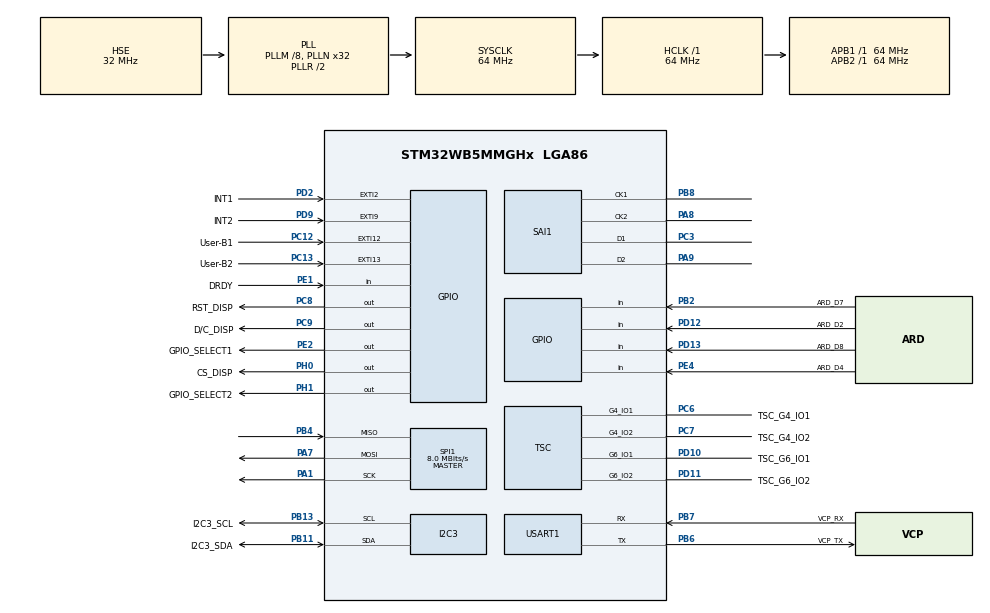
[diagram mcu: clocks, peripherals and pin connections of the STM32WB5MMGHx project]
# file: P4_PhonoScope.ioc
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Dma.Request0=SAI1_A
Dma.SAI1_A.0.Direction=DMA_PERIPH_TO_MEMORY
Dma.SAI1_A.0.EventEnable=DISABLE
Dma.SAI1_A.0.Instance=DMA1_Channel1
Dma.SAI1_A.0.MemDataAlignment=DMA_MDATAALIGN_WORD
Dma.SAI1_A.0.MemInc=DMA_MINC_ENABLE
Dma.SAI1_A.0.Mode=DMA_CIRCULAR
Dma.SAI1_A.0.PeriphDataAlignment=DMA_PDATAALIGN_WORD
Dma.SAI1_A.0.PeriphInc=DMA_PINC_DISABLE
Dma.SAI1_A.0.Polarity=HAL_DMAMUX_REQ_GEN_RISING
Dma.SAI1_A.0.Priority=DMA_PRIORITY_LOW
Dma.SAI1_A.0.RequestNumber=1
Dma.SAI1_A.0.SignalID=NONE
Dma.SAI1_A.0.SyncEnable=DISABLE
Dma.SAI1_A.0.SyncPolarity=HAL_DMAMUX_SYNC_NO_EVENT
Dma.SAI1_A.0.SyncRequestNumber=1
Dma.SAI1_A.0.SyncSignalID=NONE
FREERTOS.Tasks01=defaultTask,24,128,StartDefaultTask,Default,NULL,Dynamic,NULL,NULL
FREERTOS.configCHECK_FOR_STACK_OVERFLOW=2
FREERTOS.configTOTAL_HEAP_SIZE=16384
FREERTOS.configUSE_IDLE_HOOK=1
I2C3.SMBusAddressingMode=SMBUS_ADDRESSINGMODE_7BIT
I2C3.Timeout=0x0000830D
I2C3.Timing=0x10B17DB5
Mcu.Family=STM32WB
Mcu.Name=STM32WB5MMGHx
Mcu.Package=LGA86
NVIC.DMA1_Channel1_IRQn=true\:5\:0\:false\:false\:true\:true\:false\:true\:true
NVIC.EXTI15_10_IRQn=true\:5\:0\:false\:false\:true\:true\:true\:true\:true
NVIC.EXTI2_IRQn=true\:5\:0\:false\:false\:true\:true\:true\:true\:true
NVIC.EXTI9_5_IRQn=true\:5\:0\:false\:false\:true\:true\:true\:true\:true
NVIC.PriorityGroup=NVIC_PRIORITYGROUP_4
NVIC.SAI1_IRQn=true\:5\:0\:false\:false\:true\:true\:true\:true\:true
NVIC.TIM1_TRG_COM_TIM17_IRQn=true\:15\:0\:false\:false\:true\:false\:false\:true\:true
NVIC.TimeBase=TIM1_TRG_COM_TIM17_IRQn
NVIC.TimeBaseIP=TIM17
PA1.Mode=Full_Duplex_Master
PA1.Signal=SPI1_SCK
PA13.GPIO_Label=T_SWDIO
PA13.Signal=SYS_JTMS-SWDIO
PA14.GPIO_Label=T_SWCLK
PA14.Signal=SYS_JTCK-SWCLK
PA3.Signal=QUADSPI_CLK
PA7.Mode=Full_Duplex_Master
PA7.Signal=SPI1_MOSI
PA8.Mode=CK2
PA8.Signal=SAI1_CK2
PA9.Mode=3_4_MicroPhones
PA9.Signal=SAI1_D2
PB11.GPIO_Label=I2C3_SDA
PB11.GPIO_Pu=GPIO_PULLUP
PB11.Mode=I2C
PB11.Signal=I2C3_SDA
PB13.GPIO_Label=I2C3_SCL
PB13.GPIO_Pu=GPIO_PULLUP
PB13.Mode=I2C
PB13.Signal=I2C3_SCL
PB2.GPIO_Label=ARD_D7
PB2.Signal=GPIO_Input
PB3.GPIO_Label=T_SWO
PB3.Signal=SYS_JTDO-SWO
PB4.Mode=Full_Duplex_Master
PB4.Signal=SPI1_MISO
PB6.GPIO_Label=VCP_TX
PB6.Mode=Asynchronous
PB6.Signal=USART1_TX
PB7.GPIO_Label=VCP_RX
PB7.Mode=Asynchronous
PB7.Signal=USART1_RX
PB8.Mode=PDM_Master_Mode_CK1
PB8.Signal=SAI1_CK1
PC12.GPIO_Label=User-B1
PC12.GPIO_ModeDefaultEXTI=GPIO_MODE_IT_FALLING
PC12.GPIO_PuPd=GPIO_PULLUP
PC12.Signal=GPXTI12
PC13.GPIO_Label=User-B2
PC13.GPIO_ModeDefaultEXTI=GPIO_MODE_IT_FALLING
PC13.GPIO_PuPd=GPIO_PULLUP
PC13.Signal=GPXTI13
PC3.Mode=PDM_Master_Mode_CK1
PC3.Signal=SAI1_D1
PC6.GPIO_Label=TSC_G4_IO1
PC6.Mode=G4_IO1-Sampling
PC6.Signal=TSC_G4_IO1
PC7.GPIO_Label=TSC_G4_IO2
PC7.Mode=G4_IO2-Shield
PC7.Signal=TSC_G4_IO2
PC8.GPIO_Label=RST_DISP
PC8.Signal=GPIO_Output
PC9.GPIO_Label=D/C_DISP
PC9.Signal=GPIO_Output
PD10.GPIO_Label=TSC_G6_IO1
PD10.Mode=G6_IO1-Sampling
PD10.Signal=TSC_G6_IO1
PD11.GPIO_Label=TSC_G6_IO2
PD11.Mode=G6_IO2-Channel
PD11.Signal=TSC_G6_IO2
PD12.GPIO_Label=ARD_D2
PD12.Signal=GPIO_Input
PD13.GPIO_Label=ARD_D8
PD13.Signal=GPIO_Input
PD2.GPIO_Label=INT1
PD2.Signal=GPXTI2
PD3.Signal=QUADSPI_BK1_NCS
PD5.Signal=QUADSPI_BK1_IO1
PD7.Signal=QUADSPI_BK1_IO3
PD9.GPIO_Label=INT2
PD9.Signal=GPXTI9
PE1.GPIO_Label=DRDY
PE1.Signal=GPIO_Input
PE2.GPIO_Label=GPIO_SELECT1
PE2.Signal=GPIO_Output
PE4.GPIO_Label=ARD_D4
PE4.Signal=GPIO_Input
PH0.GPIO_Label=CS_DISP
PH0.Signal=GPIO_Output
PH1.GPIO_Label=GPIO_SELECT2
PH1.Signal=GPIO_Output
ProjectManager.HeapSize=0x200
ProjectManager.StackSize=0x400
ProjectManager.TargetToolchain=CMake
RCC.ADCFreq_Value=48000000
RCC.AHB2CLKDivider=RCC_SYSCLK_DIV2
RCC.AHBFreq_Value=64000000
RCC.APB1Freq_Value=64000000
RCC.APB1TimFreq_Value=64000000
RCC.APB2Freq_Value=64000000
RCC.APB2TimFreq_Value=64000000
RCC.APB3Freq_Value=16000000
RCC.Cortex2_Div=SYSTICK_CLKSOURCE_HCLK_DIV8
RCC.CortexFreq_Value=64000000
RCC.HCLKFreq_Value=64000000
RCC.HSE_VALUE=32000000
RCC.HSI48_VALUE=48000000
RCC.HSI_VALUE=16000000
RCC.LSE_Drive_Capability=RCC_LSEDRIVE_LOW
RCC.PLLM=RCC_PLLM_DIV8
RCC.PLLN=32
RCC.PLLSAI1N=24
RCC.PLLSourceVirtual=RCC_PLLSOURCE_HSE
RCC.SYSCLKFreq_VALUE=64000000
RCC.SYSCLKSource=RCC_SYSCLKSOURCE_PLLCLK
RCC.USBFreq_Value=48000000
RCC.VCOOutputFreq_Value=128000000
SAI1.Activation=ENABLE
SAI1.DataSize-PDM_Master_Mode_CK1=SAI_DATASIZE_8
SAI1.ErrorAudioFreq-PDM_Master_Mode_CK1=-2.34 %
SAI1.FrameLength-PDM_Master_Mode_CK1=8
SAI1.Instance-PDM_Master_Mode_CK1=SAI$Index_Block_A
SAI1.MClockEnable-PDM_Master_Mode_CK1=SAI_MASTERCLOCK_DISABLE
SAI1.RealAudioFreq-PDM_Master_Mode_CK1=187.5 KHz
SAI1.SlotActive-PDM_Master_Mode_CK1=0x0000FFFF
SAI1.SlotNumber-PDM_Master_Mode_CK1=1
SAI1.VirtualMode-PDM_Master_Mode_CK1=VM_MASTER
SAI1.VirtualProtocol-PDM_Master_Mode_CK1=VM_PDM_PROTOCOL
SAI1.VirtualSlotActive-PDM_Master_Mode_CK1=SAI_SLOTACTIVE_ALL
SPI1.BaudRatePrescaler=SPI_BAUDRATEPRESCALER_8
SPI1.CLKPolarity=SPI_POLARITY_HIGH
SPI1.CalculateBaudRate=8.0 MBits/s
SPI1.DataSize=SPI_DATASIZE_8BIT
SPI1.Direction=SPI_DIRECTION_2LINES
SPI1.Mode=SPI_MODE_MASTER
SPI1.VirtualType=VM_MASTER
TSC.AcquisitionMode=TSC_ACQ_MODE_NORMAL
TSC.ChannelIOs-G6_IO2=TSC_GROUP6_IO2
TSC.SamplingIOs-G4_IO1=TSC_GROUP4_IO1
TSC.SamplingIOs-G6_IO1=TSC_GROUP6_IO1
TSC.ShieldIOs-G4_IO2=TSC_GROUP4_IO2
TSC.SynchroPinPolarity=TSC_SYNC_POLARITY_FALLING
USART1.VirtualMode-Asynchronous=VM_ASYNC
VP_FREERTOS_VS_CMSIS_V2.Mode=CMSIS_V2
VP_MEMORYMAP_VS_MEMORYMAP.Mode=CurAppReg
VP_RCC_LSE.Mode=CRS SYNC Source LSE
VP_RCC_V_OSC32_IN.Mode=LSE-External-Clock-Source
VP_RCC_V_OSC_IN.Mode=HSE-External-Clock-Source
VP_SYS_VS_tim17.Mode=TIM17
board=STM32WB5MM-DK

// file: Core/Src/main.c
/* USER CODE BEGIN Header */
/**
  ******************************************************************************
  * @file           : main.c
  * @brief          : Main program body
  ******************************************************************************
  * @attention
  *
  * Copyright (c) 2026 STMicroelectronics.
  * All rights reserved.
  *
  * This software is licensed under terms that can be found in the LICENSE file
  * in the root directory of this software component.
  * If no LICENSE file comes with this software, it is provided AS-IS.
  *
  ******************************************************************************
  */
/* USER CODE END Header */
#include "main.h"
#include "cmsis_os2.h"
#include "FreeRTOS.h"

/* USER CODE BEGIN Includes */
#include "tasks.h"
/* USER CODE END Includes */

I2C_HandleTypeDef hi2c3;

SAI_HandleTypeDef hsai_BlockA1;
DMA_HandleTypeDef hdma_sai1_a;

SPI_HandleTypeDef hspi1;

TSC_HandleTypeDef htsc;

UART_HandleTypeDef huart1;

/* Definitions for defaultTask */
osThreadId_t defaultTaskHandle;
const osThreadAttr_t defaultTask_attributes = {
  .name = "defaultTask",
  .priority = (osPriority_t) osPriorityNormal,
  .stack_size = 128 * 4
};

void SystemClock_Config(void);
void PeriphCommonClock_Config(void);
static void MX_GPIO_Init(void);
static void MX_DMA_Init(void);
static void MX_I2C3_Init(void);
static void MX_USART1_UART_Init(void);
static void MX_SPI1_Init(void);
static void MX_TSC_Init(void);
static void MX_SAI1_Init(void);
void StartDefaultTask(void *argument);

int main(void)
{

  /* MCU Configuration--------------------------------------------------------*/

  /* Reset of all peripherals, Initializes the Flash interface and the Systick. */
  HAL_Init();

  /* Configure the system clock */
  SystemClock_Config();

  /* Configure the peripherals common clocks */
  PeriphCommonClock_Config();

  /* Initialize all configured peripherals */
  MX_GPIO_Init();
  MX_DMA_Init();
  MX_I2C3_Init();
  MX_USART1_UART_Init();
  MX_SPI1_Init();
  MX_TSC_Init();
  MX_SAI1_Init();
  /* USER CODE BEGIN 2 */
  app_post();          /* POST: sensors + flash JEDEC id + perf baseline (pre-scheduler) */
  /* USER CODE END 2 */

  /* Init scheduler */
  osKernelInitialize();

  /* Create the thread(s) */
  /* creation of defaultTask */
  defaultTaskHandle = osThreadNew(StartDefaultTask, NULL, &defaultTask_attributes);

  /* USER CODE BEGIN RTOS_THREADS */
  app_start();         /* create flash/i2c3 mutexes + vitals queue + DRDY sem + app tasks */
  /* USER CODE END RTOS_THREADS */

  /* Start scheduler */
  osKernelStart();

  /* We should never get here as control is now taken by the scheduler */

  /* Infinite loop */
  while (1)
  {

  }
}

void SystemClock_Config(void)
{
  RCC_OscInitTypeDef RCC_OscInitStruct = {0};
  RCC_ClkInitTypeDef RCC_ClkInitStruct = {0};
  RCC_CRSInitTypeDef RCC_CRSInitStruct = {0};

  /** Configure LSE Drive Capability
  */
  HAL_PWR_EnableBkUpAccess();
  __HAL_RCC_LSEDRIVE_CONFIG(RCC_LSEDRIVE_LOW);

  /** Configure the main internal regulator output voltage
  */
  __HAL_PWR_VOLTAGESCALING_CONFIG(PWR_REGULATOR_VOLTAGE_SCALE1);

  /** Initializes the RCC Oscillators according to the specified parameters
  * in the RCC_OscInitTypeDef structure.
  */
  RCC_OscInitStruct.OscillatorType = RCC_OSCILLATORTYPE_HSI|RCC_OSCILLATORTYPE_HSE
                              |RCC_OSCILLATORTYPE_LSE;
  RCC_OscInitStruct.HSEState = RCC_HSE_ON;
  RCC_OscInitStruct.LSEState = RCC_LSE_ON;
  RCC_OscInitStruct.HSIState = RCC_HSI_ON;
  RCC_OscInitStruct.HSICalibrationValue = RCC_HSICALIBRATION_DEFAULT;
  RCC_OscInitStruct.PLL.PLLState = RCC_PLL_ON;
  RCC_OscInitStruct.PLL.PLLSource = RCC_PLLSOURCE_HSE;
  RCC_OscInitStruct.PLL.PLLM = RCC_PLLM_DIV8;
  RCC_OscInitStruct.PLL.PLLN = 32;
  RCC_OscInitStruct.PLL.PLLP = RCC_PLLP_DIV2;
  RCC_OscInitStruct.PLL.PLLR = RCC_PLLR_DIV2;
  RCC_OscInitStruct.PLL.PLLQ = RCC_PLLQ_DIV2;
  if (HAL_RCC_OscConfig(&RCC_OscInitStruct) != HAL_OK)
  {
    Error_Handler();
  }

  /** Configure the SYSCLKSource, HCLK, PCLK1 and PCLK2 clocks dividers
  */
  RCC_ClkInitStruct.ClockType = RCC_CLOCKTYPE_HCLK4|RCC_CLOCKTYPE_HCLK2
                              |RCC_CLOCKTYPE_HCLK|RCC_CLOCKTYPE_SYSCLK
                              |RCC_CLOCKTYPE_PCLK1|RCC_CLOCKTYPE_PCLK2;
  RCC_ClkInitStruct.SYSCLKSource = RCC_SYSCLKSOURCE_PLLCLK;
  RCC_ClkInitStruct.AHBCLKDivider = RCC_SYSCLK_DIV1;
  RCC_ClkInitStruct.APB1CLKDivider = RCC_HCLK_DIV1;
  RCC_ClkInitStruct.APB2CLKDivider = RCC_HCLK_DIV1;
  RCC_ClkInitStruct.AHBCLK2Divider = RCC_SYSCLK_DIV2;
  RCC_ClkInitStruct.AHBCLK4Divider = RCC_SYSCLK_DIV1;

  if (HAL_RCC_ClockConfig(&RCC_ClkInitStruct, FLASH_LATENCY_3) != HAL_OK)
  {
    Error_Handler();
  }

  /** Enable the SYSCFG APB clock
  */
  __HAL_RCC_CRS_CLK_ENABLE();

  /** Configures CRS
  */
  RCC_CRSInitStruct.Prescaler = RCC_CRS_SYNC_DIV1;
  RCC_CRSInitStruct.Source = RCC_CRS_SYNC_SOURCE_LSE;
  RCC_CRSInitStruct.Polarity = RCC_CRS_SYNC_POLARITY_RISING;
  RCC_CRSInitStruct.ReloadValue = __HAL_RCC_CRS_RELOADVALUE_CALCULATE(48000000,32774);
  RCC_CRSInitStruct.ErrorLimitValue = 34;
  RCC_CRSInitStruct.HSI48CalibrationValue = 32;

  HAL_RCCEx_CRSConfig(&RCC_CRSInitStruct);
}

void PeriphCommonClock_Config(void)
{
  RCC_PeriphCLKInitTypeDef PeriphClkInitStruct = {0};

  /** Initializes the peripherals clock
  */
  PeriphClkInitStruct.PeriphClockSelection = RCC_PERIPHCLK_SMPS;
  PeriphClkInitStruct.SmpsClockSelection = RCC_SMPSCLKSOURCE_HSI;
  PeriphClkInitStruct.SmpsDivSelection = RCC_SMPSCLKDIV_RANGE1;

  if (HAL_RCCEx_PeriphCLKConfig(&PeriphClkInitStruct) != HAL_OK)
  {
    Error_Handler();
  }
}

static void MX_I2C3_Init(void)
{

  hi2c3.Instance = I2C3;
  hi2c3.Init.Timing = 0x10B17DB5;
  hi2c3.Init.OwnAddress1 = 0;
  hi2c3.Init.AddressingMode = I2C_ADDRESSINGMODE_7BIT;
  hi2c3.Init.DualAddressMode = I2C_DUALADDRESS_DISABLE;
  hi2c3.Init.OwnAddress2 = 0;
  hi2c3.Init.OwnAddress2Masks = I2C_OA2_NOMASK;
  hi2c3.Init.GeneralCallMode = I2C_GENERALCALL_DISABLE;
  hi2c3.Init.NoStretchMode = I2C_NOSTRETCH_DISABLE;
  if (HAL_I2C_Init(&hi2c3) != HAL_OK)
  {
    Error_Handler();
  }

  /** Configure Analogue filter
  */
  if (HAL_I2CEx_ConfigAnalogFilter(&hi2c3, I2C_ANALOGFILTER_ENABLE) != HAL_OK)
  {
    Error_Handler();
  }

  /** Configure Digital filter
  */
  if (HAL_I2CEx_ConfigDigitalFilter(&hi2c3, 0) != HAL_OK)
  {
    Error_Handler();
  }

}

static void MX_SAI1_Init(void)
{

  hsai_BlockA1.Instance = SAI1_Block_A;
  hsai_BlockA1.Init.Protocol = SAI_FREE_PROTOCOL;
  hsai_BlockA1.Init.AudioMode = SAI_MODEMASTER_RX;
  hsai_BlockA1.Init.DataSize = SAI_DATASIZE_8;
  hsai_BlockA1.Init.FirstBit = SAI_FIRSTBIT_MSB;
  hsai_BlockA1.Init.ClockStrobing = SAI_CLOCKSTROBING_FALLINGEDGE;
  hsai_BlockA1.Init.Synchro = SAI_ASYNCHRONOUS;
  hsai_BlockA1.Init.OutputDrive = SAI_OUTPUTDRIVE_DISABLE;
  hsai_BlockA1.Init.NoDivider = SAI_MASTERDIVIDER_ENABLE;
  hsai_BlockA1.Init.MckOverSampling = SAI_MCK_OVERSAMPLING_DISABLE;
  hsai_BlockA1.Init.FIFOThreshold = SAI_FIFOTHRESHOLD_EMPTY;
  hsai_BlockA1.Init.AudioFrequency = SAI_AUDIO_FREQUENCY_192K;
  hsai_BlockA1.Init.MonoStereoMode = SAI_STEREOMODE;
  hsai_BlockA1.Init.CompandingMode = SAI_NOCOMPANDING;
  hsai_BlockA1.Init.PdmInit.Activation = ENABLE;
  hsai_BlockA1.Init.PdmInit.MicPairsNbr = 2;
  hsai_BlockA1.Init.PdmInit.ClockEnable = SAI_PDM_CLOCK1_ENABLE | SAI_PDM_CLOCK2_ENABLE;
  hsai_BlockA1.FrameInit.FrameLength = 8;
  hsai_BlockA1.FrameInit.ActiveFrameLength = 1;
  hsai_BlockA1.FrameInit.FSDefinition = SAI_FS_STARTFRAME;
  hsai_BlockA1.FrameInit.FSPolarity = SAI_FS_ACTIVE_LOW;
  hsai_BlockA1.FrameInit.FSOffset = SAI_FS_FIRSTBIT;
  hsai_BlockA1.SlotInit.FirstBitOffset = 0;
  hsai_BlockA1.SlotInit.SlotSize = SAI_SLOTSIZE_DATASIZE;
  hsai_BlockA1.SlotInit.SlotNumber = 1;
  hsai_BlockA1.SlotInit.SlotActive = 0x0000FFFF;
  if (HAL_SAI_Init(&hsai_BlockA1) != HAL_OK)
  {
    Error_Handler();
  }

}

static void MX_SPI1_Init(void)
{

  /* SPI1 parameter configuration*/
  hspi1.Instance = SPI1;
  hspi1.Init.Mode = SPI_MODE_MASTER;
  hspi1.Init.Direction = SPI_DIRECTION_2LINES;
  hspi1.Init.DataSize = SPI_DATASIZE_8BIT;
  hspi1.Init.CLKPolarity = SPI_POLARITY_HIGH;
  hspi1.Init.CLKPhase = SPI_PHASE_1EDGE;
  hspi1.Init.NSS = SPI_NSS_SOFT;
  hspi1.Init.BaudRatePrescaler = SPI_BAUDRATEPRESCALER_8;
  hspi1.Init.FirstBit = SPI_FIRSTBIT_MSB;
  hspi1.Init.TIMode = SPI_TIMODE_DISABLE;
  hspi1.Init.CRCCalculation = SPI_CRCCALCULATION_DISABLE;
  hspi1.Init.CRCPolynomial = 7;
  hspi1.Init.CRCLength = SPI_CRC_LENGTH_DATASIZE;
  hspi1.Init.NSSPMode = SPI_NSS_PULSE_ENABLE;
  if (HAL_SPI_Init(&hspi1) != HAL_OK)
  {
    Error_Handler();
  }

}

static void MX_TSC_Init(void)
{

  /** Configure the TSC peripheral
  */
  htsc.Instance = TSC;
  htsc.Init.CTPulseHighLength = TSC_CTPH_2CYCLES;
  htsc.Init.CTPulseLowLength = TSC_CTPL_2CYCLES;
  htsc.Init.SpreadSpectrum = DISABLE;
  htsc.Init.SpreadSpectrumDeviation = 1;
  htsc.Init.SpreadSpectrumPrescaler = TSC_SS_PRESC_DIV1;
  htsc.Init.PulseGeneratorPrescaler = TSC_PG_PRESC_DIV4;
  htsc.Init.MaxCountValue = TSC_MCV_8191;
  htsc.Init.IODefaultMode = TSC_IODEF_OUT_PP_LOW;
  htsc.Init.SynchroPinPolarity = TSC_SYNC_POLARITY_FALLING;
  htsc.Init.AcquisitionMode = TSC_ACQ_MODE_NORMAL;
  htsc.Init.MaxCountInterrupt = DISABLE;
  htsc.Init.ChannelIOs = TSC_GROUP6_IO2;
  htsc.Init.ShieldIOs = TSC_GROUP4_IO2;
  htsc.Init.SamplingIOs = TSC_GROUP4_IO1|TSC_GROUP6_IO1;
  if (HAL_TSC_Init(&htsc) != HAL_OK)
  {
    Error_Handler();
  }

}

static void MX_USART1_UART_Init(void)
{

  huart1.Instance = USART1;
  huart1.Init.BaudRate = 115200;
  huart1.Init.WordLength = UART_WORDLENGTH_8B;
  huart1.Init.StopBits = UART_STOPBITS_1;
  huart1.Init.Parity = UART_PARITY_NONE;
  huart1.Init.Mode = UART_MODE_TX_RX;
  huart1.Init.HwFlowCtl = UART_HWCONTROL_NONE;
  huart1.Init.OverSampling = UART_OVERSAMPLING_16;
  huart1.Init.OneBitSampling = UART_ONE_BIT_SAMPLE_DISABLE;
  huart1.Init.ClockPrescaler = UART_PRESCALER_DIV1;
  huart1.AdvancedInit.AdvFeatureInit = UART_ADVFEATURE_NO_INIT;
  if (HAL_UART_Init(&huart1) != HAL_OK)
  {
    Error_Handler();
  }
  if (HAL_UARTEx_SetTxFifoThreshold(&huart1, UART_TXFIFO_THRESHOLD_1_8) != HAL_OK)
  {
    Error_Handler();
  }
  if (HAL_UARTEx_SetRxFifoThreshold(&huart1, UART_RXFIFO_THRESHOLD_1_8) != HAL_OK)
  {
    Error_Handler();
  }
  if (HAL_UARTEx_DisableFifoMode(&huart1) != HAL_OK)
  {
    Error_Handler();
  }

}

static void MX_DMA_Init(void)
{

  /* DMA controller clock enable */
  __HAL_RCC_DMAMUX1_CLK_ENABLE();
  __HAL_RCC_DMA1_CLK_ENABLE();

  /* DMA interrupt init */
  /* DMA1_Channel1_IRQn interrupt configuration */
  HAL_NVIC_SetPriority(DMA1_Channel1_IRQn, 5, 0);
  HAL_NVIC_EnableIRQ(DMA1_Channel1_IRQn);

}

static void MX_GPIO_Init(void)
{
  GPIO_InitTypeDef GPIO_InitStruct = {0};

  /* GPIO Ports Clock Enable */
  __HAL_RCC_GPIOA_CLK_ENABLE();
  __HAL_RCC_GPIOC_CLK_ENABLE();
  __HAL_RCC_GPIOB_CLK_ENABLE();
  __HAL_RCC_GPIOE_CLK_ENABLE();
  __HAL_RCC_GPIOH_CLK_ENABLE();
  __HAL_RCC_GPIOD_CLK_ENABLE();

  /*Configure GPIO pin Output Level */
  HAL_GPIO_WritePin(GPIOH, CS_DISP_Pin|GPIO_SELECT2_Pin, GPIO_PIN_RESET);

  /*Configure GPIO pin Output Level */
  HAL_GPIO_WritePin(GPIOC, D_C_DISP_Pin|RST_DISP_Pin, GPIO_PIN_RESET);

  /*Configure GPIO pin Output Level */
  HAL_GPIO_WritePin(GPIO_SELECT1_GPIO_Port, GPIO_SELECT1_Pin, GPIO_PIN_RESET);

  /*Configure GPIO pins : User_B1_Pin User_B2_Pin */
  GPIO_InitStruct.Pin = User_B1_Pin|User_B2_Pin;
  GPIO_InitStruct.Mode = GPIO_MODE_IT_FALLING;
  GPIO_InitStruct.Pull = GPIO_PULLUP;
  HAL_GPIO_Init(GPIOC, &GPIO_InitStruct);

  /*Configure GPIO pins : ARD_D4_Pin DRDY_Pin */
  GPIO_InitStruct.Pin = ARD_D4_Pin|DRDY_Pin;
  GPIO_InitStruct.Mode = GPIO_MODE_INPUT;
  GPIO_InitStruct.Pull = GPIO_NOPULL;
  HAL_GPIO_Init(GPIOE, &GPIO_InitStruct);

  /*Configure GPIO pin : ARD_D7_Pin */
  GPIO_InitStruct.Pin = ARD_D7_Pin;
  GPIO_InitStruct.Mode = GPIO_MODE_INPUT;
  GPIO_InitStruct.Pull = GPIO_NOPULL;
  HAL_GPIO_Init(ARD_D7_GPIO_Port, &GPIO_InitStruct);

  /*Configure GPIO pin : PA3 */
  GPIO_InitStruct.Pin = GPIO_PIN_3;
  GPIO_InitStruct.Mode = GPIO_MODE_AF_PP;
  GPIO_InitStruct.Pull = GPIO_NOPULL;
  GPIO_InitStruct.Speed = GPIO_SPEED_FREQ_LOW;
  GPIO_InitStruct.Alternate = GPIO_AF10_QUADSPI;
  HAL_GPIO_Init(GPIOA, &GPIO_InitStruct);

  /*Configure GPIO pins : CS_DISP_Pin GPIO_SELECT2_Pin */
  GPIO_InitStruct.Pin = CS_DISP_Pin|GPIO_SELECT2_Pin;
  GPIO_InitStruct.Mode = GPIO_MODE_OUTPUT_PP;
  GPIO_InitStruct.Pull = GPIO_NOPULL;
  GPIO_InitStruct.Speed = GPIO_SPEED_FREQ_LOW;
  HAL_GPIO_Init(GPIOH, &GPIO_InitStruct);

  /*Configure GPIO pins : ARD_D8_Pin ARD_D2_Pin */
  GPIO_InitStruct.Pin = ARD_D8_Pin|ARD_D2_Pin;
  GPIO_InitStruct.Mode = GPIO_MODE_INPUT;
  GPIO_InitStruct.Pull = GPIO_NOPULL;
  HAL_GPIO_Init(GPIOD, &GPIO_InitStruct);

  /*Configure GPIO pins : PD7 PD3 PD5 */
  GPIO_InitStruct.Pin = GPIO_PIN_7|GPIO_PIN_3|GPIO_PIN_5;
  GPIO_InitStruct.Mode = GPIO_MODE_AF_PP;
  GPIO_InitStruct.Pull = GPIO_NOPULL;
  GPIO_InitStruct.Speed = GPIO_SPEED_FREQ_LOW;
  GPIO_InitStruct.Alternate = GPIO_AF10_QUADSPI;
  HAL_GPIO_Init(GPIOD, &GPIO_InitStruct);

  /*Configure GPIO pins : INT1_Pin INT2_Pin */
  GPIO_InitStruct.Pin = INT1_Pin|INT2_Pin;
  GPIO_InitStruct.Mode = GPIO_MODE_IT_RISING;
  GPIO_InitStruct.Pull = GPIO_NOPULL;
  HAL_GPIO_Init(GPIOD, &GPIO_InitStruct);

  /*Configure GPIO pins : D_C_DISP_Pin RST_DISP_Pin */
  GPIO_InitStruct.Pin = D_C_DISP_Pin|RST_DISP_Pin;
  GPIO_InitStruct.Mode = GPIO_MODE_OUTPUT_PP;
  GPIO_InitStruct.Pull = GPIO_NOPULL;
  GPIO_InitStruct.Speed = GPIO_SPEED_FREQ_LOW;
  HAL_GPIO_Init(GPIOC, &GPIO_InitStruct);

  /*Configure GPIO pin : GPIO_SELECT1_Pin */
  GPIO_InitStruct.Pin = GPIO_SELECT1_Pin;
  GPIO_InitStruct.Mode = GPIO_MODE_OUTPUT_PP;
  GPIO_InitStruct.Pull = GPIO_NOPULL;
  GPIO_InitStruct.Speed = GPIO_SPEED_FREQ_LOW;
  HAL_GPIO_Init(GPIO_SELECT1_GPIO_Port, &GPIO_InitStruct);

  /* EXTI interrupt init*/
  HAL_NVIC_SetPriority(EXTI2_IRQn, 5, 0);
  HAL_NVIC_EnableIRQ(EXTI2_IRQn);

  HAL_NVIC_SetPriority(EXTI9_5_IRQn, 5, 0);
  HAL_NVIC_EnableIRQ(EXTI9_5_IRQn);

  HAL_NVIC_SetPriority(EXTI15_10_IRQn, 5, 0);
  HAL_NVIC_EnableIRQ(EXTI15_10_IRQn);

}

void StartDefaultTask(void *argument)
{
  for(;;)
  {
    osDelay(1);
  }
}

void HAL_TIM_PeriodElapsedCallback(TIM_HandleTypeDef *htim)
{
  if (htim->Instance == TIM17)
  {
    HAL_IncTick();
  }
}

void Error_Handler(void)
{
  __disable_irq();
  while (1)
  {
  }
}

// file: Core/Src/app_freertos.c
/* USER CODE BEGIN Header */
/**
  ******************************************************************************
  * File Name          : app_freertos.c
  * Description        : Code for freertos applications
  ******************************************************************************
  * @attention
  *
  * Copyright (c) 2026 STMicroelectronics.
  * All rights reserved.
  *
  * This software is licensed under terms that can be found in the LICENSE file
  * in the root directory of this software component.
  * If no LICENSE file comes with this software, it is provided AS-IS.
  *
  ******************************************************************************
  */
/* USER CODE END Header */

#include "FreeRTOS.h"
#include "task.h"
#include "main.h"

/* USER CODE BEGIN Includes */
#include "perf_mon.h"
/* USER CODE END Includes */

/* Hook prototypes */
void vApplicationIdleHook(void);
void vApplicationStackOverflowHook(TaskHandle_t xTask, char *pcTaskName);

/* USER CODE BEGIN 2 */
void vApplicationIdleHook( void )
{
   /* vApplicationIdleHook() will only be called if configUSE_IDLE_HOOK is set
   to 1 in FreeRTOSConfig.h. It will be called on each iteration of the idle
   task. It is essential that code added to this hook function never attempts
   to block in any way (for example, call xQueueReceive() with a block time
   specified, or call vTaskDelay()). If the application makes use of the
   vTaskDelete() API function (as this demo application does) then it is also
   important that vApplicationIdleHook() is permitted to return to its calling
   function, because it is the responsibility of the idle task to clean up
   memory allocated by the kernel to any task that has since been deleted. */
   g_idle_count++;   /* perf_mon CPU-utilization meter (spec R27) */
}
/* USER CODE END 2 */

/* USER CODE BEGIN 4 */
void vApplicationStackOverflowHook(TaskHandle_t xTask, char *pcTaskName)
{
   /* Run time stack overflow checking is performed if
   configCHECK_FOR_STACK_OVERFLOW is defined to 1 or 2. This hook function is
   called if a stack overflow is detected. */
}
/* USER CODE END 4 */
